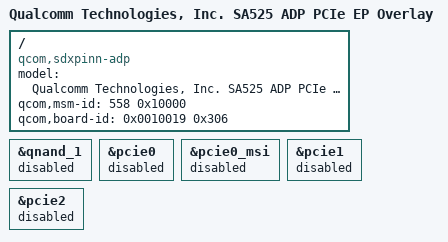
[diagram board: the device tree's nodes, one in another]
// SPDX-License-Identifier: BSD-3-Clause
/*
 * Copyright (c) Qualcomm Technologies, Inc. and/or its subsidiaries.
 */

/dts-v1/;
/plugin/;

#include "sa525m-adp.dtsi"

/ {
	model = "Qualcomm Technologies, Inc. SA525 ADP PCIe EP Overlay";
	compatible = "qcom,sdxpinn-adp",
		"qcom,sdxpinn", "qcom,adp";
	qcom,msm-id=<558 0x10000>;
	qcom,board-id = <0x0010019 0x306>;
};

&qnand_1 {
	status = "disabled";
};

&pcie0 {
	status = "disabled";
};

&pcie0_msi {
	status = "disabled";
};

&pcie1 {
	status = "disabled";
};

&pcie2 {
	status = "disabled";
};
